AUTOSAR XML (schema 3.1.2)
package /Components/SWC_TqAdpCmp
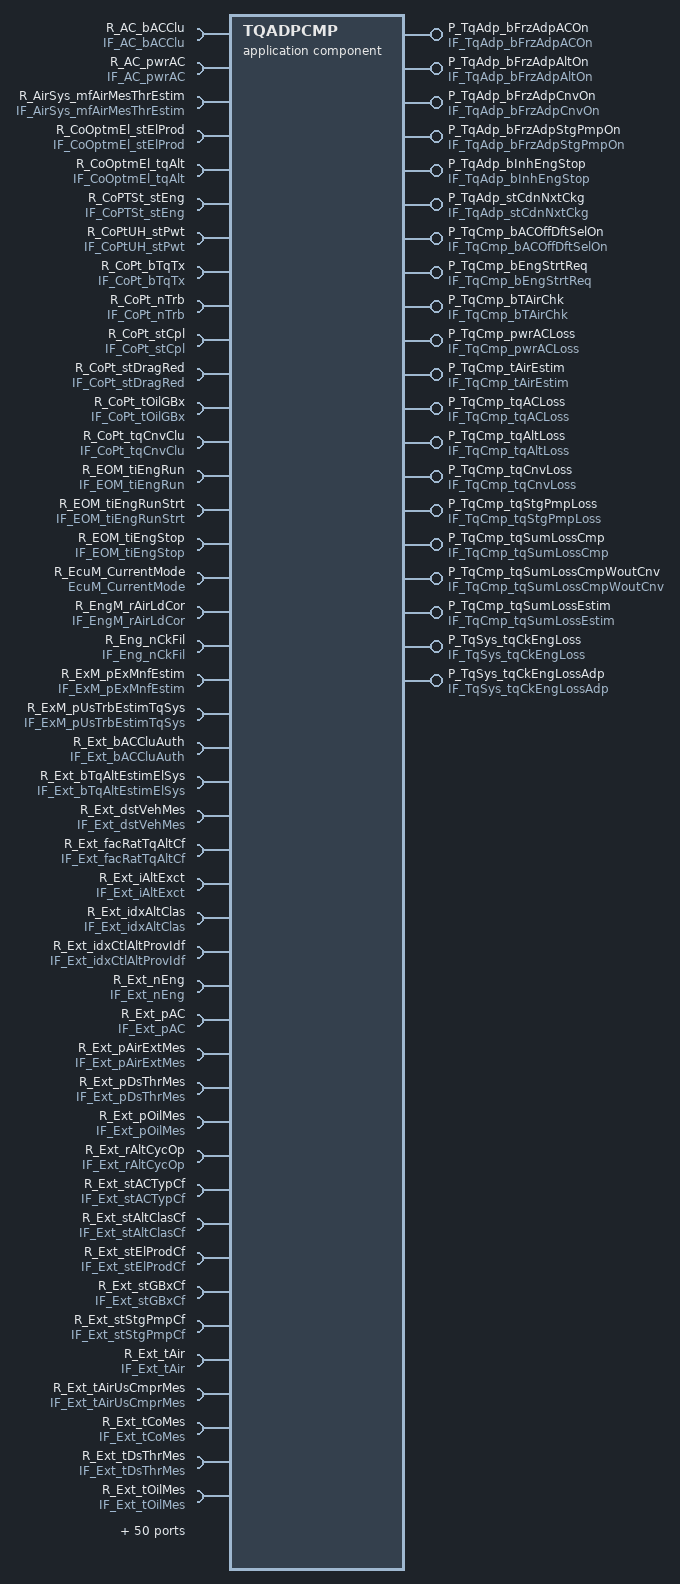
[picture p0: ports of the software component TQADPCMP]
  application software component type TQADPCMP  # TqAdpCmp
    20 x provide port:
      P_TqAdp_bFrzAdpACOn: unqueued-sender-com-spec{data-element=TqAdp_bFrzAdpACOn, can-invalidate=false, init-value=C_Boolean_False}, provided-interface=IF_TqAdp_bFrzAdpACOn
      P_TqAdp_bFrzAdpAltOn: unqueued-sender-com-spec{data-element=TqAdp_bFrzAdpAltOn, can-invalidate=false, init-value=C_Boolean_False1}, provided-interface=IF_TqAdp_bFrzAdpAltOn
      P_TqAdp_bFrzAdpCnvOn: unqueued-sender-com-spec{data-element=TqAdp_bFrzAdpCnvOn, can-invalidate=false, init-value=C_Boolean_False3}, provided-interface=IF_TqAdp_bFrzAdpCnvOn
      P_TqAdp_bFrzAdpStgPmpOn: unqueued-sender-com-spec{data-element=TqAdp_bFrzAdpStgPmpOn, can-invalidate=false, init-value=C_Boolean_False5}, provided-interface=IF_TqAdp_bFrzAdpStgPmpOn
      P_TqAdp_bInhEngStop: unqueued-sender-com-spec{data-element=TqAdp_bInhEngStop, can-invalidate=false, init-value=C_Boolean_False7}, provided-interface=IF_TqAdp_bInhEngStop
      P_TqAdp_stCdnNxtCkg: unqueued-sender-com-spec{data-element=TqAdp_stCdnNxtCkg, can-invalidate=false, init-value=ConstantValue}, provided-interface=IF_TqAdp_stCdnNxtCkg
      P_TqCmp_bACOffDftSelOn: unqueued-sender-com-spec{data-element=TqCmp_bACOffDftSelOn, can-invalidate=false, init-value=ConstantValue9}, provided-interface=IF_TqCmp_bACOffDftSelOn
      P_TqCmp_bEngStrtReq: unqueued-sender-com-spec{data-element=TqCmp_bEngStrtReq, can-invalidate=false, init-value=C_Boolean_False11}, provided-interface=IF_TqCmp_bEngStrtReq
      P_TqCmp_bTAirChk: unqueued-sender-com-spec{data-element=TqCmp_bTAirChk, can-invalidate=false, init-value=C_Boolean_False13}, provided-interface=IF_TqCmp_bTAirChk
      P_TqCmp_pwrACLoss: unqueued-sender-com-spec{data-element=TqCmp_pwrACLoss, can-invalidate=false, init-value=ConstantValue15}, provided-interface=IF_TqCmp_pwrACLoss
      P_TqCmp_tAirEstim: unqueued-sender-com-spec{data-element=TqCmp_tAirEstim, can-invalidate=false, init-value=C_SInt8_m40}, provided-interface=IF_TqCmp_tAirEstim
      P_TqCmp_tqACLoss: unqueued-sender-com-spec{data-element=TqCmp_tqACLoss, can-invalidate=false, init-value=ConstantValue17}, provided-interface=IF_TqCmp_tqACLoss
      P_TqCmp_tqAltLoss: unqueued-sender-com-spec{data-element=TqCmp_tqAltLoss, can-invalidate=false, init-value=ConstantValue19}, provided-interface=IF_TqCmp_tqAltLoss
      P_TqCmp_tqCnvLoss: unqueued-sender-com-spec{data-element=TqCmp_tqCnvLoss, can-invalidate=false, init-value=C_UInt16_0}, provided-interface=IF_TqCmp_tqCnvLoss
      P_TqCmp_tqStgPmpLoss: unqueued-sender-com-spec{data-element=TqCmp_tqStgPmpLoss, can-invalidate=false, init-value=C_UInt16_021}, provided-interface=IF_TqCmp_tqStgPmpLoss
      P_TqCmp_tqSumLossCmp: unqueued-sender-com-spec{data-element=TqCmp_tqSumLossCmp, can-invalidate=false, init-value=ConstantValue23}, provided-interface=IF_TqCmp_tqSumLossCmp
      P_TqCmp_tqSumLossCmpWoutCnv: unqueued-sender-com-spec{data-element=TqCmp_tqSumLossCmpWoutCnv, can-invalidate=false, init-value=ConstantValue25}, provided-interface=IF_TqCmp_tqSumLossCmpWoutCnv
      P_TqCmp_tqSumLossEstim: unqueued-sender-com-spec{data-element=TqCmp_tqSumLossEstim, can-invalidate=false, init-value=C_SInt16_0}, provided-interface=IF_TqCmp_tqSumLossEstim
      P_TqSys_tqCkEngLoss: unqueued-sender-com-spec{data-element=TqSys_tqCkEngLoss, can-invalidate=false, init-value=C_UInt16_027}, provided-interface=IF_TqSys_tqCkEngLoss
      P_TqSys_tqCkEngLossAdp: unqueued-sender-com-spec{data-element=TqSys_tqCkEngLossAdp, can-invalidate=false, init-value=C_SInt16_029}, provided-interface=IF_TqSys_tqCkEngLossAdp
    94 x require port:
      R_AC_bACClu: unqueued-receiver-com-spec{data-element=AC_bACClu, init-value=ConstantValue31, resync-time=0}, required-interface=IF_AC_bACClu
      R_AC_pwrAC: unqueued-receiver-com-spec{data-element=AC_pwrAC, init-value=C_UInt8_0, resync-time=0}, required-interface=IF_AC_pwrAC
      R_AirSys_mfAirMesThrEstim: unqueued-receiver-com-spec{data-element=AirSys_mfAirMesThrEstim, init-value=C_UInt16_033, resync-time=0}, required-interface=IF_AirSys_mfAirMesThrEstim
      R_CoOptmEl_stElProd: unqueued-receiver-com-spec{data-element=CoOptmEl_stElProd, init-value=ConstantValue35, resync-time=0}, required-interface=IF_CoOptmEl_stElProd
      R_CoOptmEl_tqAlt: unqueued-receiver-com-spec{data-element=CoOptmEl_tqAlt, init-value=ConstantValue37, resync-time=0}, required-interface=IF_CoOptmEl_tqAlt
      R_CoPTSt_stEng: unqueued-receiver-com-spec{data-element=CoPTSt_stEng, init-value=ConstantValue39, resync-time=0}, required-interface=IF_CoPTSt_stEng
      R_CoPtUH_stPwt: unqueued-receiver-com-spec{data-element=CoPtUH_stPwt, init-value=ConstantValue41, resync-time=0}, required-interface=IF_CoPtUH_stPwt
      R_CoPt_bTqTx: unqueued-receiver-com-spec{data-element=CoPt_bTqTx, init-value=ConstantValue43, resync-time=0}, required-interface=IF_CoPt_bTqTx
      R_CoPt_nTrb: unqueued-receiver-com-spec{data-element=CoPt_nTrb, init-value=ConstantValue45, resync-time=0}, required-interface=IF_CoPt_nTrb
      R_CoPt_stCpl: unqueued-receiver-com-spec{data-element=CoPt_stCpl, init-value=ConstantValue47, resync-time=0}, required-interface=IF_CoPt_stCpl
      R_CoPt_stDragRed: unqueued-receiver-com-spec{data-element=CoPt_stDragRed, init-value=C_UInt8_049, resync-time=0}, required-interface=IF_CoPt_stDragRed
      R_CoPt_tOilGBx: unqueued-receiver-com-spec{data-element=CoPt_tOilGBx, init-value=C_SInt16_m200, resync-time=0}, required-interface=IF_CoPt_tOilGBx
      R_CoPt_tqCnvClu: unqueued-receiver-com-spec{data-element=CoPt_tqCnvClu, init-value=C_SInt16_m32000, resync-time=0}, required-interface=IF_CoPt_tqCnvClu
      R_EOM_tiEngRun: unqueued-receiver-com-spec{data-element=EOM_tiEngRun, init-value=ConstantValue51, resync-time=0}, required-interface=IF_EOM_tiEngRun
      R_EOM_tiEngRunStrt: unqueued-receiver-com-spec{data-element=EOM_tiEngRunStrt, init-value=C_UInt16_053, resync-time=0}, required-interface=IF_EOM_tiEngRunStrt
      R_EOM_tiEngStop: unqueued-receiver-com-spec{data-element=EOM_tiEngStop, init-value=ConstantValue55, resync-time=0}, required-interface=IF_EOM_tiEngStop
      R_EcuM_CurrentMode: required-interface=EcuM_CurrentMode  # Requirement: 01552_09_00532-SSTG-C007(2)
      R_EngM_rAirLdCor: unqueued-receiver-com-spec{data-element=EngM_rAirLdCor, init-value=ConstantValue57, resync-time=0}, required-interface=IF_EngM_rAirLdCor
      R_Eng_nCkFil: unqueued-receiver-com-spec{data-element=Eng_nCkFil, init-value=ConstantValue59, resync-time=0}, required-interface=IF_Eng_nCkFil
      R_ExM_pExMnfEstim: unqueued-receiver-com-spec{data-element=ExM_pExMnfEstim, init-value=ConstantValue61, resync-time=0}, required-interface=IF_ExM_pExMnfEstim
      R_ExM_pUsTrbEstimTqSys: unqueued-receiver-com-spec{data-element=ExM_pUsTrbEstimTqSys, init-value=C_SInt16_063, resync-time=0}, required-interface=IF_ExM_pUsTrbEstimTqSys
      R_Ext_bACCluAuth: unqueued-receiver-com-spec{data-element=Ext_bACCluAuth, init-value=C_Boolean_False65, resync-time=0}, required-interface=IF_Ext_bACCluAuth
      R_Ext_bTqAltEstimElSys: unqueued-receiver-com-spec{data-element=Ext_bTqAltEstimElSys, init-value=C_Boolean_False67, resync-time=0}, required-interface=IF_Ext_bTqAltEstimElSys
      R_Ext_dstVehMes: unqueued-receiver-com-spec{data-element=Ext_dstVehMes, init-value=C_UInt32_0, resync-time=0}, required-interface=IF_Ext_dstVehMes
      R_Ext_facRatTqAltCf: unqueued-receiver-com-spec{data-element=Ext_facRatTqAltCf, init-value=ConstantValue69, resync-time=0}, required-interface=IF_Ext_facRatTqAltCf
      R_Ext_iAltExct: unqueued-receiver-com-spec{data-element=Ext_iAltExct, init-value=ConstantValue71, resync-time=0}, required-interface=IF_Ext_iAltExct
      R_Ext_idxAltClas: unqueued-receiver-com-spec{data-element=Ext_idxAltClas, init-value=C_UInt8_073, resync-time=0}, required-interface=IF_Ext_idxAltClas
      R_Ext_idxCtlAltProvIdf: unqueued-receiver-com-spec{data-element=Ext_idxCtlAltProvIdf, init-value=ConstantValue75, resync-time=0}, required-interface=IF_Ext_idxCtlAltProvIdf
      R_Ext_nEng: unqueued-receiver-com-spec{data-element=Ext_nEng, init-value=ConstantValue77, resync-time=0}, required-interface=IF_Ext_nEng
      R_Ext_pAC: unqueued-receiver-com-spec{data-element=Ext_pAC, init-value=C_UInt16_079, resync-time=0}, required-interface=IF_Ext_pAC
      R_Ext_pAirExtMes: unqueued-receiver-com-spec{data-element=Ext_pAirExtMes, init-value=ConstantValue81, resync-time=0}, required-interface=IF_Ext_pAirExtMes
      R_Ext_pDsThrMes: unqueued-receiver-com-spec{data-element=Ext_pDsThrMes, init-value=ConstantValue83, resync-time=0}, required-interface=IF_Ext_pDsThrMes
      R_Ext_pOilMes: unqueued-receiver-com-spec{data-element=Ext_pOilMes, init-value=ConstantValue85, resync-time=0}, required-interface=IF_Ext_pOilMes
      R_Ext_rAltCycOp: unqueued-receiver-com-spec{data-element=Ext_rAltCycOp, init-value=ConstantValue87, resync-time=0}, required-interface=IF_Ext_rAltCycOp
      R_Ext_stACTypCf: unqueued-receiver-com-spec{data-element=Ext_stACTypCf, init-value=ConstantValue89, resync-time=0}, required-interface=IF_Ext_stACTypCf
      R_Ext_stAltClasCf: unqueued-receiver-com-spec{data-element=Ext_stAltClasCf, init-value=ConstantValue91, resync-time=0}, required-interface=IF_Ext_stAltClasCf
      R_Ext_stElProdCf: unqueued-receiver-com-spec{data-element=Ext_stElProdCf, init-value=ConstantValue93, resync-time=0}, required-interface=IF_Ext_stElProdCf
      R_Ext_stGBxCf: unqueued-receiver-com-spec{data-element=Ext_stGBxCf, init-value=ConstantValue95, resync-time=0}, required-interface=IF_Ext_stGBxCf
      R_Ext_stStgPmpCf: unqueued-receiver-com-spec{data-element=Ext_stStgPmpCf, init-value=C_UInt8_097, resync-time=0}, required-interface=IF_Ext_stStgPmpCf
      R_Ext_tAir: unqueued-receiver-com-spec{data-element=Ext_tAir, init-value=ConstantValue99, resync-time=0}, required-interface=IF_Ext_tAir
      R_Ext_tAirUsCmprMes: unqueued-receiver-com-spec{data-element=Ext_tAirUsCmprMes, init-value=ConstantValue101, resync-time=0}, required-interface=IF_Ext_tAirUsCmprMes
      R_Ext_tCoMes: unqueued-receiver-com-spec{data-element=Ext_tCoMes, init-value=ConstantValue103, resync-time=0}, required-interface=IF_Ext_tCoMes
      R_Ext_tDsThrMes: unqueued-receiver-com-spec{data-element=Ext_tDsThrMes, init-value=ConstantValue105, resync-time=0}, required-interface=IF_Ext_tDsThrMes
      R_Ext_tOilMes: unqueued-receiver-com-spec{data-element=Ext_tOilMes, init-value=ConstantValue107, resync-time=0}, required-interface=IF_Ext_tOilMes
      R_Ext_tqAlt: unqueued-receiver-com-spec{data-element=Ext_tqAlt, init-value=C_SInt16_m32000109, resync-time=0}, required-interface=IF_Ext_tqAlt
      R_FRM_bAcvTqEngLossDftOil: required-interface=FunctionInhibition
      R_FRM_bAcvTqEngLossDftPDs: required-interface=FunctionInhibition
      R_FRM_bAcvTqEngLossDftPmp: required-interface=FunctionInhibition
      R_FRM_bAcvTqEngLossDftT: required-interface=FunctionInhibition
      R_FRM_bDftAltTyp: required-interface=FunctionInhibition
      R_FRM_bDftComAlt: required-interface=FunctionInhibition
      R_FRM_bDftElAlt: required-interface=FunctionInhibition
      R_FRM_bDftMecAlt: required-interface=FunctionInhibition
      R_FRM_bInhACExtECULossMdl: required-interface=FunctionInhibition
      R_FRM_bInhACItECULossMdl: required-interface=FunctionInhibition
      R_FRM_bInhAdp: required-interface=FunctionInhibition
      R_FRM_bInhAltLossMdl: required-interface=FunctionInhibition
      R_FRM_bInhCnvLossMdl: required-interface=FunctionInhibition
      R_FRM_bInhStgPmpLossMdl: required-interface=FunctionInhibition
      R_FRM_bInhTAirEstim: required-interface=FunctionInhibition
      R_InM_pDsThrCor: unqueued-receiver-com-spec{data-element=InM_pDsThrCor, init-value=ConstantValue111, resync-time=0}, required-interface=IF_InM_pDsThrCor
      R_Stg_bStgPmpThdMes: unqueued-receiver-com-spec{data-element=Stg_bStgPmpThdMes, init-value=C_Boolean_False113, resync-time=0}, required-interface=IF_Stg_bStgPmpThdMes
      R_Stg_pStgPmpLnrMes: unqueued-receiver-com-spec{data-element=Stg_pStgPmpLnrMes, init-value=C_UInt16_0115, resync-time=0}, required-interface=IF_Stg_pStgPmpLnrMes
      R_TqAdpCmp_GetTimer_1ms_U32: required-interface=IF_CS_FRunTime_1MS_U32
      R_TqAdp_ORngHiDragRed: required-interface=DiagnosticMonitor
      R_TqAdp_ORngHiNeut: required-interface=DiagnosticMonitor
      R_TqAdp_ORngLoDragRed: required-interface=DiagnosticMonitor
      R_TqAdp_ORngLoNeut: required-interface=DiagnosticMonitor
      R_TqAdp_bFrzAdpACAuxOn: unqueued-receiver-com-spec{data-element=TqAdp_bFrzAdpACAuxOn, init-value=C_Boolean_False117, resync-time=0}, required-interface=IF_TqAdp_bFrzAdpACAuxOn
      R_TqAdp_bFrzAdpACOn: unqueued-receiver-com-spec{data-element=TqAdp_bFrzAdpACOn, init-value=C_Boolean_False, resync-time=0}, required-interface=IF_TqAdp_bFrzAdpACOn
      R_TqAdp_bFrzAdpAltOn: unqueued-receiver-com-spec{data-element=TqAdp_bFrzAdpAltOn, init-value=C_Boolean_False119, resync-time=0}, required-interface=IF_TqAdp_bFrzAdpAltOn
      R_TqAdp_bFrzAdpCnvOn: unqueued-receiver-com-spec{data-element=TqAdp_bFrzAdpCnvOn, init-value=C_Boolean_False121, resync-time=0}, required-interface=IF_TqAdp_bFrzAdpCnvOn
      R_TqAdp_bFrzAdpStgPmpOn: unqueued-receiver-com-spec{data-element=TqAdp_bFrzAdpStgPmpOn, init-value=C_Boolean_False123, resync-time=0}, required-interface=IF_TqAdp_bFrzAdpStgPmpOn
      R_TqCmp_pwrACAuxLoss: unqueued-receiver-com-spec{data-element=TqCmp_pwrACAuxLoss, init-value=C_UInt16_0125, resync-time=0}, required-interface=IF_TqCmp_pwrACAuxLoss
      R_TqCmp_tqACLoss: unqueued-receiver-com-spec{data-element=TqCmp_tqACLoss, init-value=ConstantValue127, resync-time=0}, required-interface=IF_TqCmp_tqACLoss
      R_TqCmp_tqAltLoss: unqueued-receiver-com-spec{data-element=TqCmp_tqAltLoss, init-value=ConstantValue129, resync-time=0}, required-interface=IF_TqCmp_tqAltLoss
      R_TqCmp_tqAltRv: required-interface=DiagnosticMonitor
      R_TqCmp_tqAuxLoss: unqueued-receiver-com-spec{data-element=TqCmp_tqAuxLoss, init-value=C_UInt16_0131, resync-time=0}, required-interface=IF_TqCmp_tqAuxLoss
      R_TqCmp_tqCnvLoss: unqueued-receiver-com-spec{data-element=TqCmp_tqCnvLoss, init-value=C_UInt16_0, resync-time=0}, required-interface=IF_TqCmp_tqCnvLoss
      R_TqCmp_tqStgPmpLoss: unqueued-receiver-com-spec{data-element=TqCmp_tqStgPmpLoss, init-value=C_UInt16_0133, resync-time=0}, required-interface=IF_TqCmp_tqStgPmpLoss
      R_TqCmp_tqSumLossEstim: unqueued-receiver-com-spec{data-element=TqCmp_tqSumLossEstim, init-value=C_SInt16_m32000135, resync-time=0}, required-interface=IF_TqCmp_tqSumLossEstim
      R_TqDem_bTqGrdLim: unqueued-receiver-com-spec{data-element=TqDem_bTqGrdLim, init-value=ConstantValue137, resync-time=0}, required-interface=IF_TqDem_bTqGrdLim
      R_TqRes_bDftACSwtOn: unqueued-receiver-com-spec{data-element=TqRes_bDftACSwtOn, init-value=C_Boolean_False139, resync-time=0}, required-interface=IF_TqRes_bDftACSwtOn
      R_TqRes_tqFanStrtLoss: unqueued-receiver-com-spec{data-element=TqRes_tqFanStrtLoss, init-value=C_UInt16_0141, resync-time=0}, required-interface=IF_TqRes_tqFanStrtLoss
      R_TqSys_bEngNOnIdl: unqueued-receiver-com-spec{data-element=TqSys_bEngNOnIdl, init-value=ConstantValue143, resync-time=0}, required-interface=IF_TqSys_bEngNOnIdl
      R_TqSys_bTypFu: unqueued-receiver-com-spec{data-element=TqSys_bTypFu, init-value=ConstantValue145, resync-time=0}, required-interface=IF_TqSys_bTypFu
      R_TqSys_idxTqAccu: unqueued-receiver-com-spec{data-element=TqSys_idxTqAccu, init-value=ConstantValue147, resync-time=0}, required-interface=IF_TqSys_idxTqAccu
      R_TqSys_nTarIdl: unqueued-receiver-com-spec{data-element=TqSys_nTarIdl, init-value=ConstantValue149, resync-time=0}, required-interface=IF_TqSys_nTarIdl
      R_TqSys_tqCkEngLoss: unqueued-receiver-com-spec{data-element=TqSys_tqCkEngLoss, init-value=C_UInt16_0151, resync-time=0}, required-interface=IF_TqSys_tqCkEngLoss
      R_TqSys_tqCkEngLossAdp: unqueued-receiver-com-spec{data-element=TqSys_tqCkEngLossAdp, init-value=C_SInt16_m32000153, resync-time=0}, required-interface=IF_TqSys_tqCkEngLossAdp
      R_TqSys_tqCkIdlCmn: unqueued-receiver-com-spec{data-element=TqSys_tqCkIdlCmn, init-value=ConstantValue155, resync-time=0}, required-interface=IF_TqSys_tqCkIdlCmn
      R_TqSys_tqCkPumpHiPLoss: unqueued-receiver-com-spec{data-element=TqSys_tqCkPumpHiPLoss, init-value=C_UInt16_0157, resync-time=0}, required-interface=IF_TqSys_tqCkPumpHiPLoss
      R_UCE_stWkuMainRelSt: required-interface=IF_UCE_stWkuMainRelSt  # Requirement: 01552_09_00532-SSTG-C011(1)
      R_Veh_spdVeh: unqueued-receiver-com-spec{data-element=Veh_spdVeh, init-value=ConstantValue159, resync-time=0}, required-interface=IF_Veh_spdVeh
  96 x constant specification:
    C_Boolean_False
      value:
        boolean literal C_Boolean_False: type=DT_TqAdp_bFrzAdpACOn, value=false
    C_Boolean_False1
      value:
        boolean literal C_Boolean_False1: type=DT_TqAdp_bFrzAdpAltOn, value=false
    C_Boolean_False11
      value:
        boolean literal C_Boolean_False11: type=DT_TqCmp_bEngStrtReq, value=false
    C_Boolean_False113
      value:
        boolean literal C_Boolean_False113: type=DT_Stg_bStgPmpThdMes, value=false
    C_Boolean_False117
      value:
        boolean literal C_Boolean_False117: type=DT_TqAdp_bFrzAdpACAuxOn, value=false
    C_Boolean_False119
      value:
        boolean literal C_Boolean_False119: type=DT_TqAdp_bFrzAdpAltOn, value=false
    C_Boolean_False121
      value:
        boolean literal C_Boolean_False121: type=DT_TqAdp_bFrzAdpCnvOn, value=false
    C_Boolean_False123
      value:
        boolean literal C_Boolean_False123: type=DT_TqAdp_bFrzAdpStgPmpOn, value=false
    C_Boolean_False13
      value:
        boolean literal C_Boolean_False13: type=DT_TqCmp_bTAirChk, value=false
    C_Boolean_False139
      value:
        boolean literal C_Boolean_False139: type=DT_TqRes_bDftACSwtOn, value=false
    C_Boolean_False163
      value:
        boolean literal C_Boolean_False163: type=DT_TqCmp_bACExtECUOffDftSelOn_irv, value=false
    C_Boolean_False169
      value:
        boolean literal C_Boolean_False169: type=DT_TqAdp_bFrzAdpACExtECUOn_irv, value=false
    C_Boolean_False173
      value:
        boolean literal C_Boolean_False173: type=DT_TqAdp_bFrzAdpACItECUOn_irv, value=false
    C_Boolean_False3
      value:
        boolean literal C_Boolean_False3: type=DT_TqAdp_bFrzAdpCnvOn, value=false
    C_Boolean_False5
      value:
        boolean literal C_Boolean_False5: type=DT_TqAdp_bFrzAdpStgPmpOn, value=false
    C_Boolean_False65
      value:
        boolean literal C_Boolean_False65: type=DT_Ext_bACCluAuth, value=false
    C_Boolean_False67
      value:
        boolean literal C_Boolean_False67: type=DT_Ext_bTqAltEstimElSys, value=true
    C_Boolean_False7
      value:
        boolean literal C_Boolean_False7: type=DT_TqAdp_bInhEngStop, value=false
    C_SInt16_0
      value:
        integer literal C_SInt16_0: type=DT_TqCmp_tqSumLossEstim, value=0
    C_SInt16_0165
      value:
        integer literal C_SInt16_0165: type=DT_TqCmp_tqAuxSumLossCmp_irv, value=0
    C_SInt16_0167
      value:
        integer literal C_SInt16_0167: type=DT_TqCmp_tqAuxSumLossEstim_irv, value=0
    C_SInt16_029
      value:
        integer literal C_SInt16_029: type=DT_TqSys_tqCkEngLossAdp, value=0
    C_SInt16_063
      value:
        integer literal C_SInt16_063: type=DT_ExM_pUsTrbEstimTqSys, value=0
    C_SInt16_m200
      value:
        integer literal C_SInt16_m200: type=DT_CoPt_tOilGBx, value=160
    C_SInt16_m32000
      value:
        integer literal C_SInt16_m32000: type=DT_CoPt_tqCnvClu, value=0
    C_SInt16_m32000109
      value:
        integer literal C_SInt16_m32000109: type=DT_Ext_tqAlt, value=0
    C_SInt16_m32000135
      value:
        integer literal C_SInt16_m32000135: type=DT_TqCmp_tqSumLossEstim, value=0
    C_SInt16_m32000153
      value:
        integer literal C_SInt16_m32000153: type=DT_TqSys_tqCkEngLossAdp, value=0
    C_SInt8_m40
      value:
        integer literal C_SInt8_m40: type=DT_TqCmp_tAirEstim, value=0
    C_UInt16_0
      value:
        integer literal C_UInt16_0: type=DT_TqCmp_tqCnvLoss, value=0
    C_UInt16_0115
      value:
        integer literal C_UInt16_0115: type=DT_Stg_pStgPmpLnrMes, value=0
    C_UInt16_0125
      value:
        integer literal C_UInt16_0125: type=DT_TqCmp_pwrACAuxLoss, value=0
    C_UInt16_0131
      value:
        integer literal C_UInt16_0131: type=DT_TqCmp_tqAuxLoss, value=0
    C_UInt16_0133
      value:
        integer literal C_UInt16_0133: type=DT_TqCmp_tqStgPmpLoss, value=0
    C_UInt16_0141
      value:
        integer literal C_UInt16_0141: type=DT_TqRes_tqFanStrtLoss, value=0
    C_UInt16_0151
      value:
        integer literal C_UInt16_0151: type=DT_TqSys_tqCkEngLoss, value=0
    C_UInt16_0157
      value:
        integer literal C_UInt16_0157: type=DT_TqSys_tqCkPumpHiPLoss, value=0
    C_UInt16_0161
      value:
        integer literal C_UInt16_0161: type=DT_TqCmp_pwrACExtECULoss_irv, value=0
    C_UInt16_0171
      value:
        integer literal C_UInt16_0171: type=DT_TqCmp_pwrACItECULoss_irv, value=0
    C_UInt16_021
      value:
        integer literal C_UInt16_021: type=DT_TqCmp_tqStgPmpLoss, value=0
    C_UInt16_027
      value:
        integer literal C_UInt16_027: type=DT_TqSys_tqCkEngLoss, value=0
    C_UInt16_033
      value:
        integer literal C_UInt16_033: type=DT_AirSys_mfAirMesThrEstim, value=0
    C_UInt16_053
      value:
        integer literal C_UInt16_053: type=DT_EOM_tiEngRunStrt, value=0
    C_UInt16_079
      value:
        integer literal C_UInt16_079: type=DT_Ext_pAC, value=1000
    C_UInt32_0
      value:
        integer literal C_UInt32_0: type=DT_Ext_dstVehMes, value=0
    C_UInt8_0
      value:
        integer literal C_UInt8_0: type=DT_AC_pwrAC, value=0
    C_UInt8_049
      value:
        integer literal C_UInt8_049: type=DT_CoPt_stDragRed, value=0
    C_UInt8_073
      value:
        integer literal C_UInt8_073: type=DT_Ext_idxAltClas, value=0
    C_UInt8_097
      value:
        integer literal C_UInt8_097: type=DT_Ext_stStgPmpCf, value=0
    ConstantValue
      value:
        integer literal ConstantValue: type=DT_TqAdp_stCdnNxtCkg, value=0
    ConstantValue101
      value:
        integer literal ConstantValue101: type=DT_Ext_tAirUsCmprMes, value=20
    ConstantValue103
      value:
        integer literal ConstantValue103: type=DT_Ext_tCoMes, value=20
    ConstantValue105
      value:
        integer literal ConstantValue105: type=DT_Ext_tDsThrMes, value=25
    ConstantValue107
      value:
        integer literal ConstantValue107: type=DT_Ext_tOilMes, value=0
    ConstantValue111
      value:
        integer literal ConstantValue111: type=DT_InM_pDsThrCor, value=0
    ConstantValue127
      value:
        integer literal ConstantValue127: type=DT_TqCmp_tqACLoss, value=0
    ConstantValue129
      value:
        integer literal ConstantValue129: type=DT_TqCmp_tqAltLoss, value=0
    ConstantValue137
      value:
        boolean literal ConstantValue137: type=DT_TqDem_bTqGrdLim, value=false
    ConstantValue143
      value:
        boolean literal ConstantValue143: type=DT_TqSys_bEngNOnIdl, value=true
    ConstantValue145
      value:
        boolean literal ConstantValue145: type=DT_TqSys_bTypFu, value=false
    ConstantValue147
      value:
        integer literal ConstantValue147: type=DT_TqSys_idxTqAccu, value=1
    ConstantValue149
      value:
        integer literal ConstantValue149: type=DT_TqSys_nTarIdl, value=0
    ConstantValue15
      value:
        integer literal ConstantValue15: type=DT_TqCmp_pwrACLoss, value=0
    ConstantValue155
      value:
        integer literal ConstantValue155: type=DT_TqSys_tqCkIdlCmn, value=0
    ConstantValue159
      value:
        integer literal ConstantValue159: type=DT_Veh_spdVeh, value=0
    ConstantValue17
      value:
        integer literal ConstantValue17: type=DT_TqCmp_tqACLoss, value=0
    ConstantValue19
      value:
        integer literal ConstantValue19: type=DT_TqCmp_tqAltLoss, value=0
    ConstantValue23
      value:
        integer literal ConstantValue23: type=DT_TqCmp_tqSumLossCmp, value=0
    ConstantValue25
      value:
        integer literal ConstantValue25: type=DT_TqCmp_tqSumLossCmpWoutCnv, value=0
    ConstantValue31
      value:
        boolean literal ConstantValue31: type=DT_AC_bACClu, value=false
    ConstantValue35
      value:
        integer literal ConstantValue35: type=DT_CoOptmEl_stElProd, value=0
    ConstantValue37
      value:
        integer literal ConstantValue37: type=DT_CoOptmEl_tqAlt, value=0
    ConstantValue39
      value:
        integer literal ConstantValue39: type=DT_CoPTSt_stEng, value=1
    ConstantValue41
      value:
        integer literal ConstantValue41: type=DT_CoPtUH_stPwt, value=1
    ConstantValue43
      value:
        boolean literal ConstantValue43: type=DT_CoPt_bTqTx, value=false
    ConstantValue45
      value:
        integer literal ConstantValue45: type=DT_CoPt_nTrb, value=0
    ConstantValue47
      value:
        integer literal ConstantValue47: type=DT_CoPt_stCpl, value=0
    ConstantValue51
      value:
        integer literal ConstantValue51: type=DT_EOM_tiEngRun, value=0
    ConstantValue55
      value:
        integer literal ConstantValue55: type=DT_EOM_tiEngStop, value=864000
    ConstantValue57
      value:
        integer literal ConstantValue57: type=DT_EngM_rAirLdCor, value=0
    ConstantValue59
      value:
        integer literal ConstantValue59: type=DT_Eng_nCkFil, value=0
    ConstantValue61
      value:
        integer literal ConstantValue61: type=DT_ExM_pExMnfEstim, value=0
    ConstantValue69
      value:
        integer literal ConstantValue69: type=DT_Ext_facRatTqAltCf, value=0
    ConstantValue71
      value:
        integer literal ConstantValue71: type=DT_Ext_iAltExct, value=0
    ConstantValue75
      value:
        integer literal ConstantValue75: type=DT_Ext_idxCtlAltProvIdf, value=7
    ConstantValue77
      value:
        integer literal ConstantValue77: type=DT_Ext_nEng, value=0
    ConstantValue81
      value:
        integer literal ConstantValue81: type=DT_Ext_pAirExtMes, value=500
    ConstantValue83
      value:
        integer literal ConstantValue83: type=DT_Ext_pDsThrMes, value=1000
    ConstantValue85
      value:
        integer literal ConstantValue85: type=DT_Ext_pOilMes, value=0
    ConstantValue87
      value:
        integer literal ConstantValue87: type=DT_Ext_rAltCycOp, value=0
    ConstantValue89
      value:
        integer literal ConstantValue89: type=DT_Ext_stACTypCf, value=0
    ConstantValue9
      value:
        boolean literal ConstantValue9: type=DT_TqCmp_bACOffDftSelOn, value=false
    ConstantValue91
      value:
        integer literal ConstantValue91: type=DT_Ext_stAltClasCf, value=0
    ConstantValue93
      value:
        integer literal ConstantValue93: type=DT_Ext_stElProdCf, value=0
    ConstantValue95
      value:
        integer literal ConstantValue95: type=DT_Ext_stGBxCf, value=0
    ConstantValue99
      value:
        integer literal ConstantValue99: type=DT_Ext_tAir, value=20
  internal behavior IB_TqAdpCmp: component=TQADPCMP
    5 x timing event, all with mode-dependency=dependent-on-mode=[R_UCE_stWkuMainRelSt.RCD_stWkuMainRelSt.Invalid, R_UCE_stWkuMainRelSt.RCD_stWkuMainRelSt.PostMainWakeUp, R_UCE_stWkuMainRelSt.RCD_stWkuMainRelSt.PreMainWakeUp], period=0.01:
      EV_TqAdp_Sdl10ms_TqAdpLossClc: start-on-event=RE_TqAdp_Sdl10ms_TqAdpLossClc
      EV_TqSys_Sdl10ms_TqCmpEngLoss: start-on-event=RE_TqSys_Sdl10ms_TqCmpEngLoss
      EV_TqSys_Sdl10ms_TqCmpTqAC: start-on-event=RE_TqSys_Sdl10ms_TqCmpTqAC
      EV_TqSys_Sdl10ms_TqCmpTqAC3: start-on-event=RE_TqSys_Sdl10ms_TqCmpTqAC3
      EV_TqSys_Sdl10ms_TqCmpTqAlt: start-on-event=RE_TqSys_Sdl10ms_TqCmpTqAlt
    mode switch event EV_TqAdpCmp_001_MSE: start-on-event=RE_TqAdpCmp_001_MSE, activation=ENTRY, mode=R_EcuM_CurrentMode.currentMode.RUN
    6 x timing event, all with mode-dependency=dependent-on-mode=[R_UCE_stWkuMainRelSt.RCD_stWkuMainRelSt.Invalid, R_UCE_stWkuMainRelSt.RCD_stWkuMainRelSt.PostMainWakeUp, R_UCE_stWkuMainRelSt.RCD_stWkuMainRelSt.PreMainWakeUp]:
      EV_TqSys_Sdl10ms_TqCmpTqAC4: start-on-event=RE_TqSys_Sdl10ms_TqCmpTqAC4, period=0.01
      EV_TqSys_Sdl10ms_TqCmpTqCnv: start-on-event=RE_TqSys_Sdl10ms_TqCmpTqCnv, period=0.01
      EV_TqSys_Sdl10ms_TqCmpGlbCord: start-on-event=RE_TqSys_Sdl10ms_TqCmpGlbCord, period=0.01
      EV_TqSys_Sdl10ms_TqCmpAccCord: start-on-event=RE_TqSys_Sdl10ms_TqCmpAccCord, period=0.01
      EV_TqSys_Sdl10ms_TqCmpTqStg: start-on-event=RE_TqSys_Sdl10ms_TqCmpTqStg, period=0.01
      EV_TqSys_Sdl100ms_TqCmpTAir: start-on-event=RE_TqSys_Sdl100ms_TqCmpTAir, period=0.1
    7 x inter runnable variable, all with sw-calibration-access=READ-WRITE, communication-approach=EXPLICIT:
      TqCmp_pwrACItECULoss_irv: type=DT_TqCmp_pwrACItECULoss_irv, init-value=C_UInt16_0171
      TqAdp_bFrzAdpACExtECUOn_irv: type=DT_TqAdp_bFrzAdpACExtECUOn_irv, init-value=C_Boolean_False169
      TqAdp_bFrzAdpACItECUOn_irv: type=DT_TqAdp_bFrzAdpACItECUOn_irv, init-value=C_Boolean_False173
      TqCmp_bACExtECUOffDftSelOn_irv: type=DT_TqCmp_bACExtECUOffDftSelOn_irv, init-value=C_Boolean_False163
      TqCmp_tqAuxSumLossEstim_irv: type=DT_TqCmp_tqAuxSumLossEstim_irv, init-value=C_SInt16_0167
      TqCmp_tqAuxSumLossCmp_irv: type=DT_TqCmp_tqAuxSumLossCmp_irv, init-value=C_SInt16_0165
      TqCmp_pwrACExtECULoss_irv: type=DT_TqCmp_pwrACExtECULoss_irv, init-value=C_UInt16_0161
    12 x runnable:
      RE_TqSys_Sdl10ms_TqCmpAccCord: written-variable=[TqCmp_tqAuxSumLossCmp_irv, TqCmp_tqAuxSumLossEstim_irv]
        4 x data receive point:
          dr_TqCmp_tqStgPmpLoss: data-element=R_TqCmp_tqStgPmpLoss.TqCmp_tqStgPmpLoss
          dr_TqCmp_tqAuxLoss: data-element=R_TqCmp_tqAuxLoss.TqCmp_tqAuxLoss
          dr_TqCmp_tqAltLoss: data-element=R_TqCmp_tqAltLoss.TqCmp_tqAltLoss
          dr_TqCmp_tqACLoss: data-element=R_TqCmp_tqACLoss.TqCmp_tqACLoss
        sync call ssp_GetTimer_1ms_U32: operation=R_TqAdpCmp_GetTimer_1ms_U32.GetTimer_1ms_U32
      RE_TqSys_Sdl10ms_TqCmpTqAC4: written-variable=[TqCmp_bACExtECUOffDftSelOn_irv, TqAdp_bFrzAdpACExtECUOn_irv, TqCmp_pwrACExtECULoss_irv]
        6 x data receive point:
          dr_TqRes_bDftACSwtOn: data-element=R_TqRes_bDftACSwtOn.TqRes_bDftACSwtOn
          dr_Ext_pAC: data-element=R_Ext_pAC.Ext_pAC
          dr_AC_bACClu: data-element=R_AC_bACClu.AC_bACClu
          dr_Ext_stACTypCf: data-element=R_Ext_stACTypCf.Ext_stACTypCf
          dr_Ext_tAir: data-element=R_Ext_tAir.Ext_tAir
          dr_AC_pwrAC: data-element=R_AC_pwrAC.AC_pwrAC
        sync call ssp_FRM_bInhACExtECULossMdl: operation=R_FRM_bInhACExtECULossMdl.GetFunctionPermission
        sync call ssp_GetTimer_1ms_U32: operation=R_TqAdpCmp_GetTimer_1ms_U32.GetTimer_1ms_U32
      RE_TqSys_Sdl10ms_TqCmpTqAC: read-variable=[TqCmp_bACExtECUOffDftSelOn_irv, TqAdp_bFrzAdpACExtECUOn_irv, TqAdp_bFrzAdpACItECUOn_irv, TqCmp_pwrACItECULoss_irv, TqCmp_pwrACExtECULoss_irv]
        5 x data receive point:
          dr_TqDem_bTqGrdLim: data-element=R_TqDem_bTqGrdLim.TqDem_bTqGrdLim
          dr_Eng_nCkFil: data-element=R_Eng_nCkFil.Eng_nCkFil
          dr_TqAdp_bFrzAdpACAuxOn: data-element=R_TqAdp_bFrzAdpACAuxOn.TqAdp_bFrzAdpACAuxOn
          dr_Ext_stACTypCf: data-element=R_Ext_stACTypCf.Ext_stACTypCf
          dr_TqCmp_pwrACAuxLoss: data-element=R_TqCmp_pwrACAuxLoss.TqCmp_pwrACAuxLoss
        4 x data send point:
          ds_TqCmp_tqACLoss: data-element=P_TqCmp_tqACLoss.TqCmp_tqACLoss
          ds_TqCmp_pwrACLoss: data-element=P_TqCmp_pwrACLoss.TqCmp_pwrACLoss
          ds_TqAdp_bFrzAdpACOn: data-element=P_TqAdp_bFrzAdpACOn.TqAdp_bFrzAdpACOn
          ds_TqCmp_bACOffDftSelOn: data-element=P_TqCmp_bACOffDftSelOn.TqCmp_bACOffDftSelOn
        sync call ssp_GetTimer_1ms_U32: operation=R_TqAdpCmp_GetTimer_1ms_U32.GetTimer_1ms_U32
      RE_TqSys_Sdl10ms_TqCmpTqCnv
        9 x data receive point:
          dr_CoPt_bTqTx: data-element=R_CoPt_bTqTx.CoPt_bTqTx
          dr_TqSys_nTarIdl: data-element=R_TqSys_nTarIdl.TqSys_nTarIdl
          dr_CoPt_tOilGBx: data-element=R_CoPt_tOilGBx.CoPt_tOilGBx
          dr_CoPt_tqCnvClu: data-element=R_CoPt_tqCnvClu.CoPt_tqCnvClu
          dr_Ext_stGBxCf: data-element=R_Ext_stGBxCf.Ext_stGBxCf
          dr_Veh_spdVeh: data-element=R_Veh_spdVeh.Veh_spdVeh
          dr_CoPt_nTrb: data-element=R_CoPt_nTrb.CoPt_nTrb
          dr_CoPt_stDragRed: data-element=R_CoPt_stDragRed.CoPt_stDragRed
          dr_Eng_nCkFil: data-element=R_Eng_nCkFil.Eng_nCkFil
        data send point ds_TqAdp_bFrzAdpCnvOn: data-element=P_TqAdp_bFrzAdpCnvOn.TqAdp_bFrzAdpCnvOn
        data send point ds_TqCmp_tqCnvLoss: data-element=P_TqCmp_tqCnvLoss.TqCmp_tqCnvLoss
        sync call ssp_GetTimer_1ms_U32: operation=R_TqAdpCmp_GetTimer_1ms_U32.GetTimer_1ms_U32
        sync call ssp_FRM_bInhCnvLossMdl: operation=R_FRM_bInhCnvLossMdl.GetFunctionPermission
      RE_TqSys_Sdl10ms_TqCmpEngLoss
        14 x data receive point:
          dr_ExM_pUsTrbEstimTqSys: data-element=R_ExM_pUsTrbEstimTqSys.ExM_pUsTrbEstimTqSys
          dr_InM_pDsThrCor: data-element=R_InM_pDsThrCor.InM_pDsThrCor
          dr_Ext_pOilMes: data-element=R_Ext_pOilMes.Ext_pOilMes
          dr_EngM_rAirLdCor: data-element=R_EngM_rAirLdCor.EngM_rAirLdCor
          dr_EOM_tiEngStop: data-element=R_EOM_tiEngStop.EOM_tiEngStop
          dr_Ext_tCoMes: data-element=R_Ext_tCoMes.Ext_tCoMes
          dr_ExM_pExMnfEstim: data-element=R_ExM_pExMnfEstim.ExM_pExMnfEstim
          dr_TqSys_bTypFu: data-element=R_TqSys_bTypFu.TqSys_bTypFu
          dr_Eng_nCkFil: data-element=R_Eng_nCkFil.Eng_nCkFil
          dr_TqSys_tqCkPumpHiPLoss: data-element=R_TqSys_tqCkPumpHiPLoss.TqSys_tqCkPumpHiPLoss
          dr_Ext_nEng: data-element=R_Ext_nEng.Ext_nEng
          dr_Ext_pAirExtMes: data-element=R_Ext_pAirExtMes.Ext_pAirExtMes
          dr_Ext_tOilMes: data-element=R_Ext_tOilMes.Ext_tOilMes
          dr_Ext_pDsThrMes: data-element=R_Ext_pDsThrMes.Ext_pDsThrMes
        data send point ds_TqSys_tqCkEngLoss: data-element=P_TqSys_tqCkEngLoss.TqSys_tqCkEngLoss
        5 x sync call:
          ssp_FRM_bAcvTqEngLossDftPDs: operation=R_FRM_bAcvTqEngLossDftPDs.GetFunctionPermission
          ssp_GetTimer_1ms_U32: operation=R_TqAdpCmp_GetTimer_1ms_U32.GetTimer_1ms_U32
          ssp_FRM_bAcvTqEngLossDftT: operation=R_FRM_bAcvTqEngLossDftT.GetFunctionPermission
          ssp_FRM_bAcvTqEngLossDftPmp: operation=R_FRM_bAcvTqEngLossDftPmp.GetFunctionPermission
          ssp_FRM_bAcvTqEngLossDftOil: operation=R_FRM_bAcvTqEngLossDftOil.GetFunctionPermission
      RE_TqSys_Sdl10ms_TqCmpTqStg
        6 x data receive point:
          dr_Ext_stStgPmpCf: data-element=R_Ext_stStgPmpCf.Ext_stStgPmpCf
          dr_TqDem_bTqGrdLim: data-element=R_TqDem_bTqGrdLim.TqDem_bTqGrdLim
          dr_Eng_nCkFil: data-element=R_Eng_nCkFil.Eng_nCkFil
          dr_Stg_bStgPmpThdMes: data-element=R_Stg_bStgPmpThdMes.Stg_bStgPmpThdMes
          dr_Veh_spdVeh: data-element=R_Veh_spdVeh.Veh_spdVeh
          dr_Stg_pStgPmpLnrMes: data-element=R_Stg_pStgPmpLnrMes.Stg_pStgPmpLnrMes
        data send point ds_TqCmp_tqStgPmpLoss: data-element=P_TqCmp_tqStgPmpLoss.TqCmp_tqStgPmpLoss
        data send point ds_TqAdp_bFrzAdpStgPmpOn: data-element=P_TqAdp_bFrzAdpStgPmpOn.TqAdp_bFrzAdpStgPmpOn
        sync call ssp_GetTimer_1ms_U32: operation=R_TqAdpCmp_GetTimer_1ms_U32.GetTimer_1ms_U32
        sync call ssp_FRM_bInhStgPmpLossMdl: operation=R_FRM_bInhStgPmpLossMdl.GetFunctionPermission
      RE_TqAdpCmp_001_MSE: written-variable=[TqCmp_bACExtECUOffDftSelOn_irv, TqCmp_pwrACExtECULoss_irv, TqCmp_tqAuxSumLossEstim_irv, TqCmp_tqAuxSumLossCmp_irv, TqAdp_bFrzAdpACItECUOn_irv, TqCmp_pwrACItECULoss_irv, TqAdp_bFrzAdpACExtECUOn_irv]
        20 x data send point:
          ds_TqAdp_bFrzAdpCnvOn: data-element=P_TqAdp_bFrzAdpCnvOn.TqAdp_bFrzAdpCnvOn
          ds_TqAdp_bInhEngStop: data-element=P_TqAdp_bInhEngStop.TqAdp_bInhEngStop
          ds_TqAdp_bFrzAdpStgPmpOn: data-element=P_TqAdp_bFrzAdpStgPmpOn.TqAdp_bFrzAdpStgPmpOn
          ds_TqAdp_bFrzAdpAltOn: data-element=P_TqAdp_bFrzAdpAltOn.TqAdp_bFrzAdpAltOn
          ds_TqCmp_pwrACLoss: data-element=P_TqCmp_pwrACLoss.TqCmp_pwrACLoss
          ds_TqCmp_tqSumLossCmpWoutCnv: data-element=P_TqCmp_tqSumLossCmpWoutCnv.TqCmp_tqSumLossCmpWoutCnv
          ds_TqCmp_bTAirChk: data-element=P_TqCmp_bTAirChk.TqCmp_bTAirChk
          ds_TqSys_tqCkEngLoss: data-element=P_TqSys_tqCkEngLoss.TqSys_tqCkEngLoss
          ds_TqCmp_tqAltLoss: data-element=P_TqCmp_tqAltLoss.TqCmp_tqAltLoss
          ds_TqSys_tqCkEngLossAdp: data-element=P_TqSys_tqCkEngLossAdp.TqSys_tqCkEngLossAdp
          ds_TqAdp_stCdnNxtCkg: data-element=P_TqAdp_stCdnNxtCkg.TqAdp_stCdnNxtCkg
          ds_TqCmp_tqACLoss: data-element=P_TqCmp_tqACLoss.TqCmp_tqACLoss
          ds_TqCmp_tqSumLossEstim: data-element=P_TqCmp_tqSumLossEstim.TqCmp_tqSumLossEstim
          ds_TqCmp_tqCnvLoss: data-element=P_TqCmp_tqCnvLoss.TqCmp_tqCnvLoss
          ds_TqCmp_bACOffDftSelOn: data-element=P_TqCmp_bACOffDftSelOn.TqCmp_bACOffDftSelOn
          ds_TqCmp_tqStgPmpLoss: data-element=P_TqCmp_tqStgPmpLoss.TqCmp_tqStgPmpLoss
          ds_TqCmp_bEngStrtReq: data-element=P_TqCmp_bEngStrtReq.TqCmp_bEngStrtReq
          ds_TqAdp_bFrzAdpACOn: data-element=P_TqAdp_bFrzAdpACOn.TqAdp_bFrzAdpACOn
          ds_TqCmp_tAirEstim: data-element=P_TqCmp_tAirEstim.TqCmp_tAirEstim
          ds_TqCmp_tqSumLossCmp: data-element=P_TqCmp_tqSumLossCmp.TqCmp_tqSumLossCmp
        sync call ssp_GetTimer_1ms_U32: operation=R_TqAdpCmp_GetTimer_1ms_U32.GetTimer_1ms_U32
      RE_TqSys_Sdl10ms_TqCmpGlbCord: read-variable=[TqCmp_tqAuxSumLossCmp_irv, TqCmp_tqAuxSumLossEstim_irv]
        4 x data receive point:
          dr_TqSys_tqCkEngLossAdp: data-element=R_TqSys_tqCkEngLossAdp.TqSys_tqCkEngLossAdp
          dr_TqCmp_tqCnvLoss: data-element=R_TqCmp_tqCnvLoss.TqCmp_tqCnvLoss
          dr_CoPTSt_stEng: data-element=R_CoPTSt_stEng.CoPTSt_stEng
          dr_TqSys_tqCkEngLoss: data-element=R_TqSys_tqCkEngLoss.TqSys_tqCkEngLoss
        data send point ds_TqCmp_tqSumLossEstim: data-element=P_TqCmp_tqSumLossEstim.TqCmp_tqSumLossEstim
        data send point ds_TqCmp_tqSumLossCmp: data-element=P_TqCmp_tqSumLossCmp.TqCmp_tqSumLossCmp
        data send point ds_TqCmp_tqSumLossCmpWoutCnv: data-element=P_TqCmp_tqSumLossCmpWoutCnv.TqCmp_tqSumLossCmpWoutCnv
        sync call ssp_GetTimer_1ms_U32: operation=R_TqAdpCmp_GetTimer_1ms_U32.GetTimer_1ms_U32
      RE_TqSys_Sdl10ms_TqCmpTqAlt
        15 x data receive point:
          dr_Eng_nCkFil: data-element=R_Eng_nCkFil.Eng_nCkFil
          dr_Ext_stAltClasCf: data-element=R_Ext_stAltClasCf.Ext_stAltClasCf
          dr_TqDem_bTqGrdLim: data-element=R_TqDem_bTqGrdLim.TqDem_bTqGrdLim
          dr_Ext_tqAlt: data-element=R_Ext_tqAlt.Ext_tqAlt
          dr_TqRes_tqFanStrtLoss: data-element=R_TqRes_tqFanStrtLoss.TqRes_tqFanStrtLoss
          dr_Ext_iAltExct: data-element=R_Ext_iAltExct.Ext_iAltExct
          dr_Ext_rAltCycOp: data-element=R_Ext_rAltCycOp.Ext_rAltCycOp
          dr_CoOptmEl_tqAlt: data-element=R_CoOptmEl_tqAlt.CoOptmEl_tqAlt
          dr_Ext_idxAltClas: data-element=R_Ext_idxAltClas.Ext_idxAltClas
          dr_CoPTSt_stEng: data-element=R_CoPTSt_stEng.CoPTSt_stEng
          dr_CoPtUH_stPwt: data-element=R_CoPtUH_stPwt.CoPtUH_stPwt
          dr_Ext_idxCtlAltProvIdf: data-element=R_Ext_idxCtlAltProvIdf.Ext_idxCtlAltProvIdf
          dr_Ext_bTqAltEstimElSys: data-element=R_Ext_bTqAltEstimElSys.Ext_bTqAltEstimElSys
          dr_Ext_stElProdCf: data-element=R_Ext_stElProdCf.Ext_stElProdCf
          dr_Ext_facRatTqAltCf: data-element=R_Ext_facRatTqAltCf.Ext_facRatTqAltCf
        data send point ds_TqCmp_tqAltLoss: data-element=P_TqCmp_tqAltLoss.TqCmp_tqAltLoss
        data send point ds_TqAdp_bFrzAdpAltOn: data-element=P_TqAdp_bFrzAdpAltOn.TqAdp_bFrzAdpAltOn
        7 x sync call:
          ssp_GetTimer_1ms_U32: operation=R_TqAdpCmp_GetTimer_1ms_U32.GetTimer_1ms_U32
          ssp_FRM_bDftComAlt: operation=R_FRM_bDftComAlt.GetFunctionPermission
          ssp_TqCmp_tqAltRv: operation=R_TqCmp_tqAltRv.SetEventStatus
          ssp_FRM_bDftElAlt: operation=R_FRM_bDftElAlt.GetFunctionPermission
          ssp_FRM_bDftMecAlt: operation=R_FRM_bDftMecAlt.GetFunctionPermission
          ssp_FRM_bInhAltLossMdl: operation=R_FRM_bInhAltLossMdl.GetFunctionPermission
          ssp_FRM_bDftAltTyp: operation=R_FRM_bDftAltTyp.GetFunctionPermission
      RE_TqAdp_Sdl10ms_TqAdpLossClc
        23 x data receive point:
          dr_CoOptmEl_stElProd: data-element=R_CoOptmEl_stElProd.CoOptmEl_stElProd
          dr_Ext_tOilMes: data-element=R_Ext_tOilMes.Ext_tOilMes
          dr_TqAdp_bFrzAdpACOn: data-element=R_TqAdp_bFrzAdpACOn.TqAdp_bFrzAdpACOn
          dr_CoPt_stCpl: data-element=R_CoPt_stCpl.CoPt_stCpl
          dr_TqSys_nTarIdl: data-element=R_TqSys_nTarIdl.TqSys_nTarIdl
          dr_CoPt_stDragRed: data-element=R_CoPt_stDragRed.CoPt_stDragRed
          dr_TqCmp_tqSumLossEstim: data-element=R_TqCmp_tqSumLossEstim.TqCmp_tqSumLossEstim
          dr_EOM_tiEngRunStrt: data-element=R_EOM_tiEngRunStrt.EOM_tiEngRunStrt
          dr_TqSys_bEngNOnIdl: data-element=R_TqSys_bEngNOnIdl.TqSys_bEngNOnIdl
          dr_Ext_tCoMes: data-element=R_Ext_tCoMes.Ext_tCoMes
          dr_Ext_stGBxCf: data-element=R_Ext_stGBxCf.Ext_stGBxCf
          dr_TqSys_tqCkIdlCmn: data-element=R_TqSys_tqCkIdlCmn.TqSys_tqCkIdlCmn
          dr_Eng_nCkFil: data-element=R_Eng_nCkFil.Eng_nCkFil
          dr_CoPt_bTqTx: data-element=R_CoPt_bTqTx.CoPt_bTqTx
          dr_Veh_spdVeh: data-element=R_Veh_spdVeh.Veh_spdVeh
          dr_Ext_dstVehMes: data-element=R_Ext_dstVehMes.Ext_dstVehMes
          dr_TqAdp_bFrzAdpAltOn: data-element=R_TqAdp_bFrzAdpAltOn.TqAdp_bFrzAdpAltOn
          dr_TqCmp_tqACLoss: data-element=R_TqCmp_tqACLoss.TqCmp_tqACLoss
          dr_TqAdp_bFrzAdpStgPmpOn: data-element=R_TqAdp_bFrzAdpStgPmpOn.TqAdp_bFrzAdpStgPmpOn
          dr_AC_bACClu: data-element=R_AC_bACClu.AC_bACClu
          dr_CoPTSt_stEng: data-element=R_CoPTSt_stEng.CoPTSt_stEng
          dr_TqSys_idxTqAccu: data-element=R_TqSys_idxTqAccu.TqSys_idxTqAccu
          dr_TqAdp_bFrzAdpCnvOn: data-element=R_TqAdp_bFrzAdpCnvOn.TqAdp_bFrzAdpCnvOn
        data send point ds_TqAdp_bInhEngStop: data-element=P_TqAdp_bInhEngStop.TqAdp_bInhEngStop
        data send point ds_TqSys_tqCkEngLossAdp: data-element=P_TqSys_tqCkEngLossAdp.TqSys_tqCkEngLossAdp
        data send point ds_TqAdp_stCdnNxtCkg: data-element=P_TqAdp_stCdnNxtCkg.TqAdp_stCdnNxtCkg
        6 x sync call:
          ssp_TqAdp_ORngHiNeut: operation=R_TqAdp_ORngHiNeut.SetEventStatus
          ssp_TqAdp_ORngLoDragRed: operation=R_TqAdp_ORngLoDragRed.SetEventStatus
          ssp_TqAdp_ORngLoNeut: operation=R_TqAdp_ORngLoNeut.SetEventStatus
          ssp_TqAdp_ORngHiDragRed: operation=R_TqAdp_ORngHiDragRed.SetEventStatus
          ssp_FRM_bInhAdp: operation=R_FRM_bInhAdp.GetFunctionPermission
          ssp_GetTimer_1ms_U32: operation=R_TqAdpCmp_GetTimer_1ms_U32.GetTimer_1ms_U32
      RE_TqSys_Sdl100ms_TqCmpTAir
        9 x data receive point:
          dr_Ext_tAirUsCmprMes: data-element=R_Ext_tAirUsCmprMes.Ext_tAirUsCmprMes
          dr_Veh_spdVeh: data-element=R_Veh_spdVeh.Veh_spdVeh
          dr_EOM_tiEngRun: data-element=R_EOM_tiEngRun.EOM_tiEngRun
          dr_EOM_tiEngStop: data-element=R_EOM_tiEngStop.EOM_tiEngStop
          dr_Ext_tDsThrMes: data-element=R_Ext_tDsThrMes.Ext_tDsThrMes
          dr_CoPTSt_stEng: data-element=R_CoPTSt_stEng.CoPTSt_stEng
          dr_TqSys_bTypFu: data-element=R_TqSys_bTypFu.TqSys_bTypFu
          dr_Ext_tCoMes: data-element=R_Ext_tCoMes.Ext_tCoMes
          dr_AirSys_mfAirMesThrEstim: data-element=R_AirSys_mfAirMesThrEstim.AirSys_mfAirMesThrEstim
        data send point ds_TqCmp_bTAirChk: data-element=P_TqCmp_bTAirChk.TqCmp_bTAirChk
        data send point ds_TqCmp_bEngStrtReq: data-element=P_TqCmp_bEngStrtReq.TqCmp_bEngStrtReq
        data send point ds_TqCmp_tAirEstim: data-element=P_TqCmp_tAirEstim.TqCmp_tAirEstim
        sync call ssp_FRM_bInhTAirEstim: operation=R_FRM_bInhTAirEstim.GetFunctionPermission
        sync call ssp_GetTimer_1ms_U32: operation=R_TqAdpCmp_GetTimer_1ms_U32.GetTimer_1ms_U32
      RE_TqSys_Sdl10ms_TqCmpTqAC3: written-variable=[TqAdp_bFrzAdpACItECUOn_irv, TqCmp_pwrACItECULoss_irv]
        5 x data receive point:
          dr_Ext_stACTypCf: data-element=R_Ext_stACTypCf.Ext_stACTypCf
          dr_Ext_tAir: data-element=R_Ext_tAir.Ext_tAir
          dr_Ext_pAC: data-element=R_Ext_pAC.Ext_pAC
          dr_Eng_nCkFil: data-element=R_Eng_nCkFil.Eng_nCkFil
          dr_Ext_bACCluAuth: data-element=R_Ext_bACCluAuth.Ext_bACCluAuth
        sync call ssp_GetTimer_1ms_U32: operation=R_TqAdpCmp_GetTimer_1ms_U32.GetTimer_1ms_U32
        sync call ssp_FRM_bInhACItECULossMdl: operation=R_FRM_bInhACItECULossMdl.GetFunctionPermission
  swc implementation Imp_TqAdpCmp: programming-language=C, behavior=IB_TqAdpCmp
    code-descriptors:
      code CodeDescriptor: type=SRC
        20 x xfile:
          TQADPCMP_Calc_Tq_Applicable_c: url=TQADPCMP_Calc_Tq_Applicable.c
          TQADPCMP_nvm_c: url=TQADPCMP_nvm.c
          TQADPCMP_Calc_Running_Tq_c: url=TQADPCMP_Calc_Running_Tq.c
          TQADPCMP_Coord_Accessory_Ls_c: url=TQADPCMP_Coord_Accessory_Ls.c
          TQADPCMP_Estim_Air_Cond_T3_c: url=TQADPCMP_Estim_Air_Cond_T3.c
          TqAdpCmp_c: url=TqAdpCmp.c
          TQADPCMP_Estim_Alternator_c: url=TQADPCMP_Estim_Alternator.c
          TQADPCMP_Estim_Air_Cond_c: url=TQADPCMP_Estim_Air_Cond.c
          TQADPCMP_Allow_Inhibit_Stt_c: url=TQADPCMP_Allow_Inhibit_Stt.c
          TqAdpCmp_h: url=TqAdpCmp.h
          TQADPCMP_Coord_Global_Loss_c: url=TQADPCMP_Coord_Global_Loss.c
          TQADPCMP_Estim_Bva_c: url=TQADPCMP_Estim_Bva.c
          TQADPCMP_Estim_Air_Cond_T4_c: url=TQADPCMP_Estim_Air_Cond_T4.c
          TQADPCMP_nvm_h: url=TQADPCMP_nvm.h
          TQADPCMP_Temp_Engine_c: url=TQADPCMP_Temp_Engine.c
          TQADPCMP_Model_Tair_c: url=TQADPCMP_Model_Tair.c
          TQADPCMP_Estim_Steering_c: url=TQADPCMP_Estim_Steering.c
          TQADPCMP_Loss_Nvm_c: url=TQADPCMP_Loss_Nvm.c
          TqAdpCmp_MemMap_h: url=TqAdpCmp_MemMap.h
          TQADPCMP_Coord_Lost_Motor_c: url=TQADPCMP_Coord_Lost_Motor.c
package /Components/SWC_TqAdpCmp/TqAdpCmp_IRVDatatypes
  boolean type DT_TqAdp_bFrzAdpACExtECUOn_irv: base-type=boolean
  boolean type DT_TqAdp_bFrzAdpACItECUOn_irv: base-type=boolean
  boolean type DT_TqCmp_bACExtECUOffDftSelOn_irv: base-type=boolean
  4 x integer type:
    DT_TqCmp_pwrACExtECULoss_irv: base-type=uint16, lower-limit=0, upper-limit=65535
    DT_TqCmp_pwrACItECULoss_irv: base-type=uint16, lower-limit=0, upper-limit=65535
    DT_TqCmp_tqAuxSumLossCmp_irv: base-type=int16, lower-limit=-32768, upper-limit=32767
    DT_TqCmp_tqAuxSumLossEstim_irv: base-type=int16, lower-limit=-32768, upper-limit=32767
